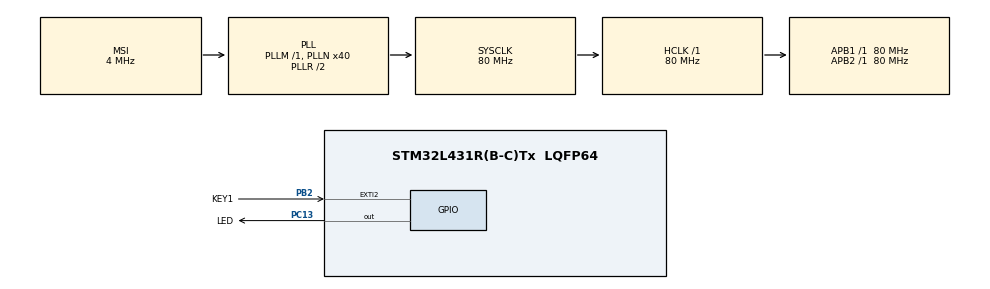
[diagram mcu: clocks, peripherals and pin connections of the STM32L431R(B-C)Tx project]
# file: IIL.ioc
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Mcu.Family=STM32L4
Mcu.Name=STM32L431R(B-C)Tx
Mcu.Package=LQFP64
NVIC.EXTI2_IRQn=true\:0\:0\:false\:false\:true\:true\:true
NVIC.PriorityGroup=NVIC_PRIORITYGROUP_4
PB2.GPIO_Label=KEY1
PB2.GPIO_PuPd=GPIO_PULLUP
PB2.Signal=GPXTI2
PC13.GPIO_Label=LED
PC13.Signal=GPIO_Output
ProjectManager.HeapSize=0x200
ProjectManager.StackSize=0x400
ProjectManager.TargetToolchain=MDK-ARM V5.27
RCC.AHBFreq_Value=80000000
RCC.APB1Freq_Value=80000000
RCC.APB1TimFreq_Value=80000000
RCC.APB2Freq_Value=80000000
RCC.APB2TimFreq_Value=80000000
RCC.CortexFreq_Value=80000000
RCC.HCLKFreq_Value=80000000
RCC.HSE_VALUE=8000000
RCC.HSI48_VALUE=48000000
RCC.HSI_VALUE=16000000
RCC.LSE_VALUE=32768
RCC.MSI_VALUE=4000000
RCC.PLLN=40
RCC.SYSCLKFreq_VALUE=80000000
RCC.SYSCLKSource=RCC_SYSCLKSOURCE_PLLCLK
RCC.VCOOutputFreq_Value=160000000
board=custom

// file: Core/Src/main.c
/* USER CODE BEGIN Header */
/**
  ******************************************************************************
  * @file           : main.c
  * @brief          : Main program body
  ******************************************************************************
  * @attention
  *
  * <h2><center>&copy; Copyright (c) 2021 STMicroelectronics.
  * All rights reserved.</center></h2>
  *
  * This software component is licensed by ST under BSD 3-Clause license,
  * the "License"; You may not use this file except in compliance with the
  * License. You may obtain a copy of the License at:
  *                        opensource.org/licenses/BSD-3-Clause
  *
  ******************************************************************************
  */
/* USER CODE END Header */
#include "main.h"
#include "gpio.h"

enum s_Led_Mode_Value{
	twinkleMode = 0,
	breathMode = 1
} v_Led_Mode = twinkleMode;

void SystemClock_Config(void);
/* USER CODE BEGIN PFP */
void delay_us(uint32_t us);
/* USER CODE END PFP */

int main(void)
{

  /* MCU Configuration--------------------------------------------------------*/

  /* Reset of all peripherals, Initializes the Flash interface and the Systick. */
  HAL_Init();

  /* Configure the system clock */
  SystemClock_Config();

  /* Initialize all configured peripherals */
  MX_GPIO_Init();

  /* Infinite loop */
  while (1)
  {

		/* USER CODE BEGIN 3 */

		/********1.常亮 begin*********************/
		HAL_GPIO_WritePin( LED_GPIO_Port, LED_Pin, 1); //1为亮
		HAL_Delay(5000); //常亮5s
		HAL_GPIO_WritePin( LED_GPIO_Port, LED_Pin, 0); //让灯熄灭
		HAL_Delay(1000); //延时1秒
		/*********1.常亮 end**********************/

		/************2.闪烁（亮 0.5s 灭 0.5s） begin*********/
		for(int t = 0;t < 10; t++){  //循环10次
			HAL_GPIO_TogglePin( LED_GPIO_Port, LED_Pin); //切换状态
			HAL_Delay(500);		//延时500毫秒
		}
		HAL_Delay(1000); //延时1秒
		/**************2.闪烁 end****************************/

		/**************3.呼吸灯模式 begin**********/
		v_Led_Mode = breathMode; //呼吸灯模式

		for(int timeCount = 0, changetime = -200 , num = 0; num < 10 ;  ){
				for(int timeCount2 = 0; timeCount2 < 10; timeCount2++){
					HAL_GPIO_WritePin(LED_GPIO_Port, LED_Pin, GPIO_PIN_SET);
					delay_us(timeCount/10);
					HAL_GPIO_WritePin(LED_GPIO_Port, LED_Pin, GPIO_PIN_RESET);
					delay_us(2000-timeCount/10);
				}
				if(timeCount>=20000||timeCount<=0){
						changetime = -changetime;
						num = num + 1;
				}
				timeCount+=changetime;

		}

		HAL_GPIO_WritePin( LED_GPIO_Port, LED_Pin, 0); //让灯熄灭
		HAL_Delay(1000); //延时1秒
		/**************3.呼吸灯模式 end ************************************/
  }
  /* USER CODE END 3 */
}

void SystemClock_Config(void)
{
  RCC_OscInitTypeDef RCC_OscInitStruct = {0};
  RCC_ClkInitTypeDef RCC_ClkInitStruct = {0};

  /** Initializes the RCC Oscillators according to the specified parameters
  * in the RCC_OscInitTypeDef structure.
  */
  RCC_OscInitStruct.OscillatorType = RCC_OSCILLATORTYPE_MSI;
  RCC_OscInitStruct.MSIState = RCC_MSI_ON;
  RCC_OscInitStruct.MSICalibrationValue = 0;
  RCC_OscInitStruct.MSIClockRange = RCC_MSIRANGE_6;
  RCC_OscInitStruct.PLL.PLLState = RCC_PLL_ON;
  RCC_OscInitStruct.PLL.PLLSource = RCC_PLLSOURCE_MSI;
  RCC_OscInitStruct.PLL.PLLM = 1;
  RCC_OscInitStruct.PLL.PLLN = 40;
  RCC_OscInitStruct.PLL.PLLP = RCC_PLLP_DIV7;
  RCC_OscInitStruct.PLL.PLLQ = RCC_PLLQ_DIV2;
  RCC_OscInitStruct.PLL.PLLR = RCC_PLLR_DIV2;
  if (HAL_RCC_OscConfig(&RCC_OscInitStruct) != HAL_OK)
  {
    Error_Handler();
  }
  /** Initializes the CPU, AHB and APB buses clocks
  */
  RCC_ClkInitStruct.ClockType = RCC_CLOCKTYPE_HCLK|RCC_CLOCKTYPE_SYSCLK
                              |RCC_CLOCKTYPE_PCLK1|RCC_CLOCKTYPE_PCLK2;
  RCC_ClkInitStruct.SYSCLKSource = RCC_SYSCLKSOURCE_PLLCLK;
  RCC_ClkInitStruct.AHBCLKDivider = RCC_SYSCLK_DIV1;
  RCC_ClkInitStruct.APB1CLKDivider = RCC_HCLK_DIV1;
  RCC_ClkInitStruct.APB2CLKDivider = RCC_HCLK_DIV1;

  if (HAL_RCC_ClockConfig(&RCC_ClkInitStruct, FLASH_LATENCY_4) != HAL_OK)
  {
    Error_Handler();
  }
  /** Configure the main internal regulator output voltage
  */
  if (HAL_PWREx_ControlVoltageScaling(PWR_REGULATOR_VOLTAGE_SCALE1) != HAL_OK)
  {
    Error_Handler();
  }
}

/* USER CODE BEGIN 4 */
void HAL_GPIO_EXTI_Callback(uint16_t GPIO_Pin)
 {

		if(v_Led_Mode == twinkleMode){
			v_Led_Mode = breathMode;
		}else if(v_Led_Mode == breathMode){
			v_Led_Mode = twinkleMode;
		}
 }

void delay_us(uint32_t us)
{
    uint32_t delay = (HAL_RCC_GetHCLKFreq() / 4000000 * us);
    while (delay--)
	{
		;
	}
}
/* USER CODE END 4 */

void Error_Handler(void)
{
  __disable_irq();
  while (1)
  {
  }
}

/************************ (C) COPYRIGHT STMicroelectronics *****END OF FILE****/
